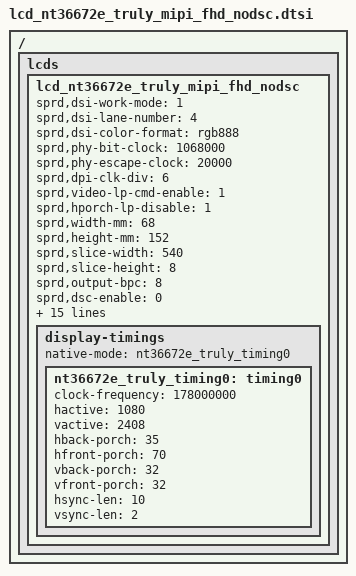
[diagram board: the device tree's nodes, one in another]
// SPDX-License-Identifier: (Licenseref-Unisoc-General-1.0 OR GPL-2.0-only)
/*
 * lcd_nt36672e_truly_mipi_fhd_nodsc.dtsi - Unisoc platform device
 *
 * Copyright 2022 Unisoc(Shanghai) Technologies Co.Ltd
 *
 * Licensed under the Unisoc General Software License, version 1.0 (the
 * License);
 * you may not use this file except in compliance with the License.
 * You may obtain a copy of the License at
 * https://www.unisoc.com/en_us/license/UNISOC_GENERAL_LICENSE_V1.0-EN_US
 * Software distributed under the License is distributed on an "AS IS" BASIS,
 * WITHOUT WARRANTIES OF ANY KIND, either express or implied.
 * See the Unisoc General Software License, version 1.0 for more details.
 *
 * Alternatively you can use and distribute this file under the terms of the
 * GNU General Public License version 2, provided that it has to be used
 *  (including but not limited to combining, linking) with any other file under
 * the GNU General Public License version 2 on platforms that use Unisoc Chips.
 */

/ {
	fragment {
		target-path = "/";
		__overlay__ {
			lcds {
				lcd_nt36672e_truly_mipi_fhd_nodsc: lcd_nt36672e_truly_mipi_fhd_nodsc {

					sprd,dsi-work-mode = <1>; /* video burst mode*/
					sprd,dsi-lane-number = <4>;
					sprd,dsi-color-format = "rgb888";

					sprd,phy-bit-clock = <1068000>;  /* kbps */
					sprd,phy-escape-clock = <20000>;/* kHz */

					sprd,dpi-clk-div = <6>;
					sprd,video-lp-cmd-enable = <1>;
					sprd,hporch-lp-disable = <1>;

					sprd,width-mm = <68>;
					sprd,height-mm = <152>;

					sprd,slice-width = <540>;
					sprd,slice-height = <8>;
					sprd,output-bpc = <8>;
					sprd,dsc-enable = <0>;
					sprd,dual-dsi-enable = <0>;

					sprd,esd-check-enable = <1>;
					sprd,esd-check-mode = <0>;  // 0:Reg mode 1:TE mode
					sprd,esd-check-period = <1000>;
					sprd,esd-check-register = <0x0A>;
					sprd,esd-check-value = <0x9C>;

					sprd,reset-on-sequence = <1 15>, <0 15>, <1 15>;
					sprd,reset-off-sequence = <0 5>;

					sprd,use-gen-write;
				sprd,initial-command = [
					15 00 00 02 FF 10
					15 00 00 02 FB 01
					15 00 00 02 B0 00
					15 00 00 02 C0 00
					29 00 00 11 C1 89 28 00 08 00 AA 02 0E 00 2B 00 07 0D B7 0C B7
					29 00 00 03 C2 1B A0

					15 00 00 02 FF 20
					15 00 00 02 FB 01
					15 00 00 02 01 66
					15 00 00 02 06 40
					15 00 00 02 07 38
					15 00 00 02 2F 83
					15 00 00 02 69 91
					15 00 00 02 95 D1
					15 00 00 02 96 D1
					15 00 00 02 F2 64
					15 00 00 02 F3 54
					15 00 00 02 F4 64
					15 00 00 02 F5 54
					15 00 00 02 F6 64
					15 00 00 02 F7 54
					15 00 00 02 F8 64
					15 00 00 02 F9 54

					/*15 00 00 02 89 1C
					15 00 00 02 8A 1C
					15 00 00 02 8B 1C
					15 00 00 02 8C 1C*/

					15 00 00 02 FF 24
					15 00 00 02 FB 01
					15 00 00 02 01 0F
					15 00 00 02 03 0C
					15 00 00 02 05 1D
					15 00 00 02 08 2F
					15 00 00 02 09 2E
					15 00 00 02 0A 2D
					15 00 00 02 0B 2C
					15 00 00 02 11 17
					15 00 00 02 12 13
					15 00 00 02 13 15
					15 00 00 02 15 14
					15 00 00 02 16 16
					15 00 00 02 17 18
					15 00 00 02 1B 01
					15 00 00 02 1D 1D
					15 00 00 02 20 2F
					15 00 00 02 21 2E
					15 00 00 02 22 2D
					15 00 00 02 23 2C
					15 00 00 02 29 17
					15 00 00 02 2A 13
					15 00 00 02 2B 15
					15 00 00 02 2F 14
					15 00 00 02 30 16
					15 00 00 02 31 18
					15 00 00 02 32 04
					15 00 00 02 34 10
					15 00 00 02 35 1F
					15 00 00 02 36 1F
					15 00 00 02 4D 14
					15 00 00 02 4E 36
					15 00 00 02 4F 36
					15 00 00 02 53 36
					15 00 00 02 71 30
					15 00 00 02 79 11
					15 00 00 02 7A 82
					15 00 00 02 7B 8F
					15 00 00 02 7D 04
					15 00 00 02 80 04
					15 00 00 02 81 04
					15 00 00 02 82 13
					15 00 00 02 84 31
					15 00 00 02 85 00
					15 00 00 02 86 00
					15 00 00 02 87 00
					15 00 00 02 90 13
					15 00 00 02 92 31
					15 00 00 02 93 00
					15 00 00 02 94 00
					15 00 00 02 95 00
					15 00 00 02 9C F4
					15 00 00 02 9D 01
					15 00 00 02 A0 0F
					15 00 00 02 A2 0F
					15 00 00 02 A3 02
					15 00 00 02 A4 04
					15 00 00 02 A5 04
					15 00 00 02 C6 C0
					15 00 00 02 C9 00
					15 00 00 02 D9 80
					15 00 00 02 E9 02

					15 00 00 02 FF 25
					15 00 00 02 FB 01
					15 00 00 02 18 22
					15 00 00 02 19 E4
					15 00 00 02 21 40
					15 00 00 02 66 D8
					15 00 00 02 68 50
					15 00 00 02 69 10
					15 00 00 02 6B 00
					15 00 00 02 6D 0D
					15 00 00 02 6E 48
					15 00 00 02 72 41
					15 00 00 02 73 4A
					15 00 00 02 74 D0
					15 00 00 02 77 62
					15 00 00 02 79 7E
					15 00 00 02 7D 03
					15 00 00 02 84 4D
					15 00 00 02 CF 80
					15 00 00 02 D6 80
					15 00 00 02 D7 80
					15 00 00 02 EF 20
					15 00 00 02 F0 84

					15 00 00 02 FF 26
					15 00 00 02 FB 01
					15 00 00 02 81 0F
					15 00 00 02 83 01
					15 00 00 02 84 03
					15 00 00 02 85 01
					15 00 00 02 86 03
					15 00 00 02 87 01
					15 00 00 02 88 05
					15 00 00 02 8A 1A
					15 00 00 02 8B 11
					15 00 00 02 8C 24
					15 00 00 02 8E 42
					15 00 00 02 8F 11
					15 00 00 02 90 11
					15 00 00 02 91 11
					15 00 00 02 9A 80
					15 00 00 02 9B 04
					15 00 00 02 9C 00
					15 00 00 02 9D 00
					15 00 00 02 9E 00

					15 00 00 02 FF 27
					15 00 00 02 FB 01
					15 00 00 02 01 68
					15 00 00 02 20 81
					15 00 00 02 21 6A
					15 00 00 02 25 81
					15 00 00 02 26 94
					15 00 00 02 6E 00
					15 00 00 02 6F 00
					15 00 00 02 70 00
					15 00 00 02 71 00
					15 00 00 02 72 00
					15 00 00 02 75 00
					15 00 00 02 76 00
					15 00 00 02 77 00
					15 00 00 02 7D 09
					15 00 00 02 7E 67
					15 00 00 02 80 23
					15 00 00 02 82 09
					15 00 00 02 83 67
					15 00 00 02 88 01
					15 00 00 02 89 10
					15 00 00 02 A5 10
					15 00 00 02 A6 23
					15 00 00 02 A7 01
					15 00 00 02 B6 40
					15 00 00 02 E5 02
					15 00 00 02 E6 D3
					15 00 00 02 EB 03
					15 00 00 02 EC 28

					15 00 00 02 FF 2A
					15 00 00 02 FB 01
					15 00 00 02 00 91
					15 00 00 02 03 20
					15 00 00 02 07 50
					15 00 00 02 0A 70
					15 00 00 02 0C 04
					15 00 00 02 0D 40
					15 00 00 02 0F 01
					15 00 00 02 11 E0
					15 00 00 02 15 0F
					15 00 00 02 16 A4
					15 00 00 02 19 0F
					15 00 00 02 1A 78
					15 00 00 02 1B 23
					15 00 00 02 1D 36
					15 00 00 02 1E 3E
					15 00 00 02 1F 3E
					15 00 00 02 20 3E
					15 00 00 02 28 FD
					15 00 00 02 29 12
					15 00 00 02 2A E1
					15 00 00 02 2D 0A
					15 00 00 02 30 49
					15 00 00 02 33 96
					15 00 00 02 34 FF
					15 00 00 02 35 40
					15 00 00 02 36 DE
					15 00 00 02 37 F9
					15 00 00 02 38 45
					15 00 00 02 39 D9
					15 00 00 02 3A 49
					15 00 00 02 4A F0
					15 00 00 02 7A 09
					15 00 00 02 7B 40
					15 00 00 02 7F F0
					15 00 00 02 83 0F
					15 00 00 02 84 A4
					15 00 00 02 87 0F
					15 00 00 02 88 78
					15 00 00 02 89 23
					15 00 00 02 8B 36
					15 00 00 02 8C 7D
					15 00 00 02 8D 7D
					15 00 00 02 8E 7D

					15 00 00 02 FF 2C
					15 00 00 02 FB 01
					15 00 00 02 61 1F
					15 00 00 02 62 1F

					15 00 00 02 7E 03
					15 00 00 02 6A 14
					15 00 00 02 6B 36
					15 00 00 02 6C 36
					15 00 00 02 6D 36
					15 00 00 02 53 04
					15 00 00 02 54 04
					15 00 00 02 55 04
					15 00 00 02 56 0F
					15 00 00 02 58 0F
					15 00 00 02 59 0F

					15 00 00 02 FF  20
					15 00 00 02 FB  01
					39 00 00 11 B0  00  E2  00  E9  00  F6  01  01  01  0C  01  15  01  20  01  28
					39 00 00 11 B1  01  33  01  51  01  6E  01  9A  01  C0  01  FD  02  34  02  35
					39 00 00 11 B2  02  6B  02  A9  02  D1  03  04  03  25  03  51  03  5F  03  6D
					39 00 00 0f B3  03  7D  03  90  03  A7  03  BB  03  D4  03  D8  00  00
					39 00 00 11 B4  00  AA  00  B3  00  C4  00  D4  00  E2  00  F0  00  FC  01  08
					39 00 00 11 B5  01  12  01  39  01  58  01  8C  01  B5  01  F7  02  30  02  31
					39 00 00 11 B6  02  68  02  A6  02  CE  03  01  03  23  03  4E  03  5C  03  6A
					39 00 00 0f B7  03  7B  03  8E  03  A5  03  BB  03  D4  03  D8  00  00
					39 00 00 11 B8  00  00  00  20  00  47  00  65  00  85  00  99  00  AD  00  C0
					39 00 00 11 B9  00  D2  01  06  01  30  01  70  01  9F  01  E8  02  25  02  26
					39 00 00 11 BA  02  5F  02  9F  02  C7  02  FD  03  20  03  52  03  63  03  67
					39 00 00 0f BB  03  78  03  8B  03  A3  03  B9  03  D4  03  D8  00  00
					15 00 00 02 FF  21
					15 00 00 02 FB  01
					39 00 00 11 B0  00  E2  00  E9  00  F6  01  01  01  0C  01  15  01  20  01  28
					39 00 00 11 B1  01  33  01  51  01  6E  01  9A  01  C0  01  FD  02  34  02  35
					39 00 00 11 B2  02  6B  02  A9  02  D1  03  04  03  25  03  51  03  5F  03  6D
					39 00 00 0f B3  03  7D  03  90  03  A7  03  BB  03  D4  03  D8  00  00
					39 00 00 11 B4  00  AA  00  B3  00  C4  00  D4  00  E2  00  F0  00  FC  01  08
					39 00 00 11 B5  01  12  01  39  01  58  01  8C  01  B5  01  F7  02  30  02  31
					39 00 00 11 B6  02  68  02  A6  02  CE  03  01  03  23  03  4E  03  5C  03  6A
					39 00 00 0f B7  03  7B  03  8E  03  A5  03  BB  03  D4  03  D8  00  00
					39 00 00 11 B8  00  00  00  20  00  47  00  65  00  85  00  99  00  AD  00  C0
					39 00 00 11 B9  00  D2  01  06  01  30  01  70  01  9F  01  E8  02  25  02  26
					39 00 00 11 BA  02  5F  02  9F  02  C7  02  FD  03  20  03  52  03  63  03  67
					39 00 00 0f BB  03  78  03  8B  03  A3  03  B9  03  D4  03  D8  00  00

					15 00 00 02 FF F0
					15 00 00 02 FB 01
					15 00 00 02 5A 00
					15 00 00 02 FF 10

					05 C8 00 01 11
					05 32 00 01 29
					];

					sprd,sleep-in-command = [
						13 0A 00 01 28
						13 78 00 01 10
					];
					sprd,sleep-out-command = [
						13 78 00 01 11
						13 32 00 01 29
					];

						display-timings {
						native-mode = <&nt36672e_truly_timing0>;

						nt36672e_truly_timing0: timing0 {
							clock-frequency = <178000000>;
							hactive = <1080>;
							vactive = <2408>;
							hback-porch = <35>;
							hfront-porch = <70>;
							vback-porch = <32>;
							vfront-porch = <32>;
							hsync-len = <10>;
							vsync-len = <2>;
						};
				};
			};
		};
	};
  };
};
